# cslr_idle register map
Vendor: Texas Instruments
Peripheral module from a debugger description file (folder C5517).
Address unit: 16 bits
Registers are 16-bit, access not given, reset 0x0 unless marked. A register's access mark holds for its fields unless they carry their own. Offsets are as the file gives them; lines under a group give offsets from that group; [hi:lo] are bit positions; {n}, {i} and the like mark numbered series; 'fields as' and 'values as' point back to an identical list; <NAME> marks a mode.

## IDLE — The DSP idle module controls the DSP and Ports idle.
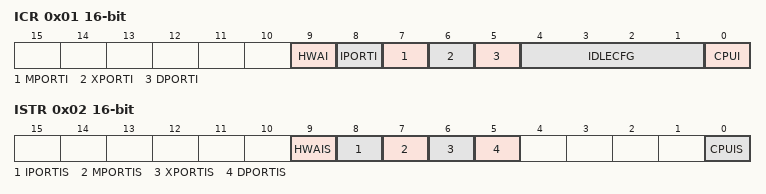
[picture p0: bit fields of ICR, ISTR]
0x01 ICR — IDLE Configuration Register
  [9] HWAI rw — UMA Hardware Accelerators Idle Control: 0 = Hardware Accelerators remain active after execution of an IDLE instruction. 1 = Hardware Accelerators are disabled after execution of an IDLE instruction.
    0=ACTIVE (Port is active); 1=IDLE (Port is idle)
  [8] IPORTI rw — UMA Instruction Port Idle Control: 0 = Instruction Port remains active after execution of an IDLE instruction. 1 = Instruction Port is disabled after execution of an IDLE instruction.
    0=ACTIVE (Port is active); 1=IDLE (Port is idle)
  [7] MPORTI rw — UMA Memory Port Idle Control: 0 = Memory Port remains active after execution of an IDLE instruction. 1 = Memory Port is disabled after execution of an IDLE instruction.
    0=ACTIVE (Port is active); 1=IDLE (Port is idle)
  [6] XPORTI rw — UMA I/O Port Idle Control: 0 = I/O Port remains active after execution of an IDLE instruction. 1 = I/O Port is disabled after execution of an IDLE instruction.
    0=ACTIVE (Port is active); 1=IDLE (Port is idle)
  [5] DPORTI rw — UMA Data Port Idle Control: 0 = Data Port remains active after execution of an IDLE instruction. 1 = Data Port is disabled after execution of an IDLE instruction.
    0=ACTIVE (Port is active); 1=IDLE (Port is idle)
  [4:1] IDLECFG rw — set bit 1, 2 and 3 to 1 and bit 4 to 0 before executing the idle instruction
  [0] CPUI rw — CPU Idle Control: 0 = CPU module remains active after execution of an IDLE instruction. 1 = CPU module is disabled after execution of an IDLE instruction.
    0=ACTIVE (Port is active); 1=IDLE (Port is idle)
0x02 ISTR — IDLE Status Register
  [all] fields
    0=ACTIVE (Port is active); 1=DISABLE (Port is disable)
  [9] HWAIS rw — UMA Hardware Accelerators Idle Status: 0 = Hardware Accelerators are active. 1 = Hardware Accelerators are disabled.
  [8] IPORTIS rw — UMA Instruction Port Idle Status: 0 = Instruction Port is active. 1 = Instruction Port is disabled.
  [7] MPORTIS rw — UMA Memory Port Idle Status: 0 = Memory Port is active. 1 = Memory Port is disabled.
  [6] XPORTIS rw — UMA I/O Port Idle Status: 0 = I/O Port is active. 1 = I/O Port is disabled.
  [5] DPORTIS rw — UMA Data Port Idle Status: 0 = Data Port is active 1 = Data Port is disabled.
  [0] CPUIS rw — CPU Idle Status: 0 = CPU module is active. 1 = CPU module is disabled.
